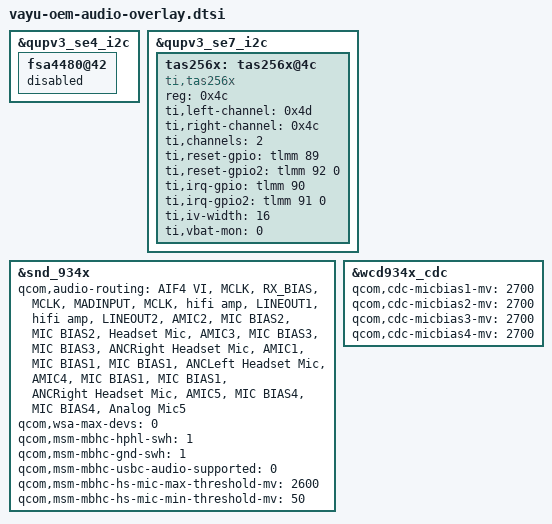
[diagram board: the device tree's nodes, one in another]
/*
 * Copyright (c) 2018, The Linux Foundation. All rights reserved.
 *
 * This program is free software; you can redistribute it and/or modify
 * it under the terms of the GNU General Public License version 2 and
 * only version 2 as published by the Free Software Foundation.
 *
 * This program is distributed in the hope that it will be useful,
 * but WITHOUT ANY WARRANTY; without even the implied warranty of
 * MERCHANTABILITY or FITNESS FOR A PARTICULAR PURPOSE.  See the
 * GNU General Public License for more details.
 */

#include "../../sm8150-audio-overlay.dtsi"

&qupv3_se4_i2c {
	status = "ok";
	fsa4480@42 {
		status = "disabled";
	};
};

&qupv3_se7_i2c {
	status = "ok";
	tas256x:tas256x@4c {
		#sound-dai-cells = <0>;
		compatible = "ti,tas256x";/*or "ti,tas2564" or "ti,tas256x" */
		reg = <0x4c>;//register tas256x_i2c_driver
		ti,left-channel = <0x4d>;  //receiver address
		ti,right-channel = <0x4c>; //speaker address
		ti,channels = <2>; /* channel number */
		ti,reset-gpio = <&tlmm 89 0>;  //SPKR_RST1
		ti,reset-gpio2 = <&tlmm 92 0>;  //SPKR_RST2
		pinctrl-names = "default";
		//pinctrl-0 = <&reset_stat_default>;
		//ti,reset-gpio = <&pm6150l_gpios 8 GPIO_ACTIVE_LOW>;
		ti,irq-gpio = <&tlmm 90 0>;//spkr_int1 left
		ti,irq-gpio2 = <&tlmm 91 0>;//spkr_int2 right
		status = "ok";
		ti,iv-width = <16>;
		ti,vbat-mon = <0>;
	};
};

&snd_934x {
	qcom,audio-routing =
		"AIF4 VI", "MCLK",
		"RX_BIAS", "MCLK",
		"MADINPUT", "MCLK",
		"hifi amp", "LINEOUT1",
		"hifi amp", "LINEOUT2",
		"AMIC2", "MIC BIAS2",
		"MIC BIAS2", "Headset Mic",
		"AMIC3", "MIC BIAS3",
		"MIC BIAS3", "ANCRight Headset Mic",
		"AMIC1", "MIC BIAS1",
		"MIC BIAS1", "ANCLeft Headset Mic",
		"AMIC4", "MIC BIAS1",
		"MIC BIAS1", "ANCRight Headset Mic",
		"AMIC5", "MIC BIAS4",
		"MIC BIAS4", "Analog Mic5";

	qcom,wsa-max-devs = <0>;
	qcom,msm-mbhc-hphl-swh = <1>;
	qcom,msm-mbhc-gnd-swh = <1>;
	qcom,msm-mbhc-usbc-audio-supported = <0>;
	qcom,msm-mbhc-hs-mic-max-threshold-mv = <2600>;
	qcom,msm-mbhc-hs-mic-min-threshold-mv = <50>;
};

&wcd934x_cdc {
	qcom,cdc-micbias1-mv = <2700>;
	qcom,cdc-micbias2-mv = <2700>;
	qcom,cdc-micbias3-mv = <2700>;
	qcom,cdc-micbias4-mv = <2700>;
};
